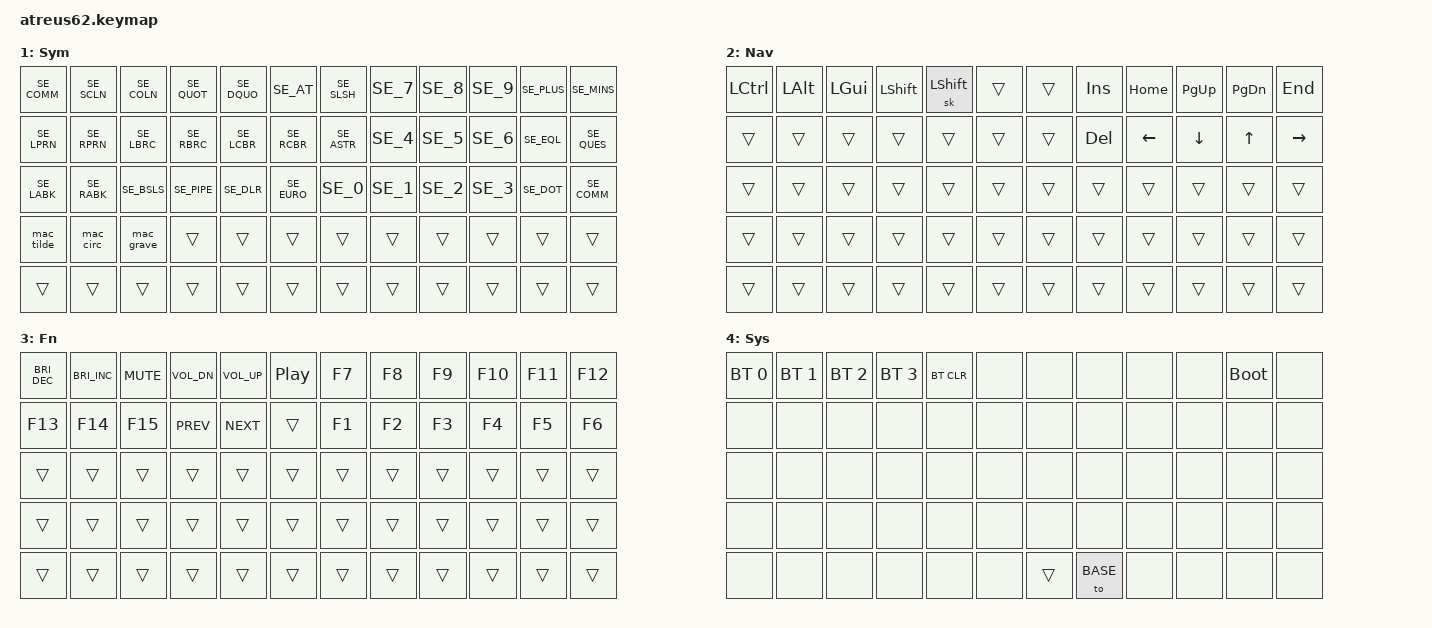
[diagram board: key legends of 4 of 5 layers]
/*
 * Atreus62 — Colemak-DH, sv-SE host
 * 5x13, gap at column 6 on rows 0-3, transform 12/12/12/12/14.
 *
 *  0  1  2  3  4  5 |  6  7  8  9 10 11
 * 12 13 14 15 16 17 | 18 19 20 21 22 23
 * 24 25 26 27 28 29 | 30 31 32 33 34 35
 * 36 37 38 39 40 41 | 42 43 44 45 46 47
 * 48 49 50 51 52 53   54 55 56 57 58 59 60 61
 */

#include <behaviors.dtsi>
#include <dt-bindings/zmk/keys.h>
#include <dt-bindings/zmk/bt.h>
#include <dt-bindings/zmk/outputs.h>

#include "keys_se.h"

#define BASE 0
#define SYM  1
#define NAV  2
#define FN   3
#define SYS  4

&sk {
    ignore-modifiers;
};

/ {
    macros {
        mac_tilde: mac_tilde {
            compatible = "zmk,behavior-macro";
            #binding-cells = <0>;
            bindings = <&kp SE_TILD>, <&kp SPACE>;
        };
        mac_circ: mac_circ {
            compatible = "zmk,behavior-macro";
            #binding-cells = <0>;
            bindings = <&kp SE_CIRC>, <&kp SPACE>;
        };
        mac_grave: mac_grave {
            compatible = "zmk,behavior-macro";
            #binding-cells = <0>;
            bindings = <&kp SE_GRV>, <&kp SPACE>;
        };
    };

    combos {
        compatible = "zmk,combos";

        combo_tab      { timeout-ms = <35>; key-positions = <14 15>; layers = <BASE>; bindings = <&kp TAB>; };
        combo_esc      { timeout-ms = <35>; key-positions = <15 16>; layers = <BASE>; bindings = <&kp ESC>; };
        combo_hyphen   { timeout-ms = <35>; key-positions = <38 40>; layers = <BASE>; bindings = <&kp SE_MINS>; };
        combo_slash    { timeout-ms = <35>; key-positions = <39 41>; layers = <BASE>; bindings = <&kp SE_SLSH>; };
        combo_capsword { timeout-ms = <35>; key-positions = <26 28>; layers = <BASE>; bindings = <&caps_word>; };
        combo_lgui     { timeout-ms = <35>; key-positions = <20 21>; layers = <BASE>; bindings = <&sk LGUI>; };
    };

    keymap {
        compatible = "zmk,keymap";

        base_layer {
            label = "Base";
            bindings = <
&kp ESC   &kp SE_1   &kp SE_2   &kp SE_3   &kp SE_4   &kp SE_5    &kp SE_6   &kp SE_7   &kp SE_8   &kp SE_9        &kp SE_0    &kp BSPC
&kp TAB   &kp SE_Q   &kp SE_W   &kp SE_F   &kp SE_P   &kp SE_B    &kp SE_J   &kp SE_L   &kp SE_U   &kp SE_Y        &kp SE_ARNG &kp DEL
&kp LSHFT &kp SE_A   &kp SE_R   &kp SE_S   &kp SE_T   &kp SE_G    &kp SE_M   &kp SE_N   &kp SE_E   &kp SE_ODIA     &kp SE_ADIA &kp RET
&kp LCTL  &kp SE_Z   &kp SE_X   &kp SE_C   &kp SE_D   &kp SE_V    &kp SE_K   &kp SE_H   &kp SE_O   &kp SE_I        &kp SE_DOT  &kp SE_COMM
&kp LCTL  &kp C_MUTE &kp C_VOL_DN &kp C_VOL_UP &kp RALT &kp LALT   &lt SYM SPACE   &lt NAV RET   &kp LGUI &kp SE_MINS &kp SE_SLSH &kp LEFT &kp DOWN &kp RIGHT
            >;
        };

        sym_layer {
            label = "Sym";
            bindings = <
&kp SE_COMM &kp SE_SCLN &kp SE_COLN &kp SE_QUOT &kp SE_DQUO &kp SE_AT      &kp SE_SLSH &kp SE_7 &kp SE_8 &kp SE_9 &kp SE_PLUS  &kp SE_MINS
&kp SE_LPRN &kp SE_RPRN &kp SE_LBRC &kp SE_RBRC &kp SE_LCBR &kp SE_RCBR    &kp SE_ASTR &kp SE_4 &kp SE_5 &kp SE_6 &kp SE_EQL   &kp SE_QUES
&kp SE_LABK &kp SE_RABK &kp SE_BSLS &kp SE_PIPE &kp SE_DLR  &kp SE_EURO    &kp SE_0    &kp SE_1 &kp SE_2 &kp SE_3 &kp SE_DOT   &kp SE_COMM
&mac_tilde  &mac_circ   &mac_grave &trans       &trans      &trans         &trans      &trans   &trans   &trans   &trans       &trans
&trans      &trans      &trans     &trans       &trans      &trans         &trans      &trans   &trans   &trans   &trans       &trans
            >;
        };

        nav_layer {
            label = "Nav";
            bindings = <
&kp LCTL  &kp LALT  &kp LGUI  &kp LSHFT  &sk LSHFT  &trans   &trans  &kp INS   &kp HOME  &kp PG_UP  &kp PG_DN  &kp END
&trans    &trans    &trans    &trans     &trans     &trans   &trans  &kp DEL   &kp LEFT  &kp DOWN   &kp UP     &kp RIGHT
&trans    &trans    &trans    &trans     &trans     &trans   &trans  &trans    &trans    &trans     &trans     &trans
&trans    &trans    &trans    &trans     &trans     &trans   &trans  &trans    &trans    &trans     &trans     &trans
&trans    &trans    &trans    &trans     &trans     &trans   &trans  &trans    &trans    &trans     &trans     &trans
            >;
        };

        fn_layer {
            label = "Fn";
            bindings = <
&kp C_BRI_DEC &kp C_BRI_INC &kp C_MUTE &kp C_VOL_DN &kp C_VOL_UP &kp C_PP    &kp F7  &kp F8  &kp F9  &kp F10  &kp F11  &kp F12
&kp F13       &kp F14       &kp F15    &kp C_PREV   &kp C_NEXT   &trans      &kp F1  &kp F2  &kp F3  &kp F4   &kp F5   &kp F6
&trans        &trans        &trans     &trans       &trans       &trans      &trans  &trans  &trans  &trans   &trans   &trans
&trans        &trans        &trans     &trans       &trans       &trans      &trans  &trans  &trans  &trans   &trans   &trans
&trans        &trans        &trans     &trans       &trans       &trans      &trans  &trans  &trans  &trans   &trans   &trans
            >;
        };

        sys_layer {
            label = "Sys";
            bindings = <
&bt BT_SEL 0 &bt BT_SEL 1 &bt BT_SEL 2 &bt BT_SEL 3 &bt BT_CLR &none   &none &none &none &none &bootloader &none
&none &none &none &none &none &none   &none &none &none &none &none &none
&none &none &none &none &none &none   &none &none &none &none &none &none
&none &none &none &none &none &none   &none &none &none &none &none &none
&none &none &none &none &none &none   &trans &to BASE &none &none &none &none
            >;
        };
    };
};
